# HR_C7000_DM32 register map
Vendor: Dahua Technology (chip); Baofeng (radio product); Series: HR_C7000; File version: 0.1-dm32re-draft
CPU: other r0p0, little endian, no MPU, no FPU, 0 interrupt priority bits
Registers are 32-bit, read-write, reset 0x0 unless marked. A register's access mark holds for its fields unless they carry their own. Offsets are from the block's base; [hi:lo] are bit positions.

## CODEC — Audio codec control registers, byte-wide (DS §6.5, Register Table 26, p.443-472; base 0x1600_09C0, inside the Modem_Buffer window). Mic inputs, DAC/ADC power and soft mute, digital mixer and AGC/DRC (the latter through indirect windows), gains, sample-rate selection and a countdown timer. Register names match PSPEC. FW: no access found by the movih scan (QEMU: dm32_codec logs named control writes).
Base 0x160009C0
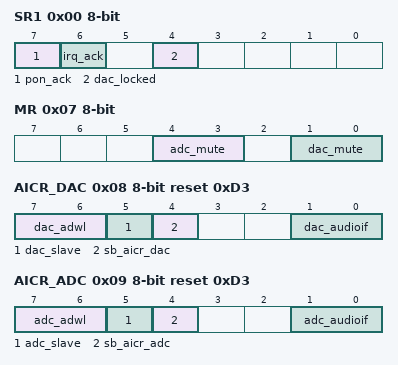
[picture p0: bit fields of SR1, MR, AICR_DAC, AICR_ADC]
0x00 SR1 8-bit ro — Status Register. DS §6.5.2.1 p.443. Reset 0x0 (DS).
  [7] pon_ack — codec power on status response 0 : codec is not in working mode; 1 : codec is in working mode [reset 0x0] [access RO]
  [6] irq_ack — Interrupt pending status register 0 : No pending interrupts are included; 1 : There is currently an unresponsive interrupt. [reset 0x0] [access RO]
  [4] dac_locked — DAC ADAS lock status, 1 is valid ( this function is in the current application Not involved ) [reset 0x0] [access RO]
0x01 SR2 8-bit ro — Status Register. DS §6.5.2.2 p.445. Reset 0x0 (DS).
  [4] dac_unknown_fs — DAC_ADAS response flag after locking: 0 : The FS of the input signal is within the frequency range supported by the codec ; 1 : The FS of the input signal exceeds the range supported by the codec ( the The performance index cannot be guaranteed). This function is not involved in the current application . [reset 0x0] [access RO]
0x07 MR 8-bit ro — ADC Mute control. DS §6.5.2.3 p.445. Reset 0x0 (DS).
  [4:3] adc_mute — 00 : ADC is not muted; 01 : ADC is being muted; 10 : ADC is about to end the mute state; 11 : ADC is in mute state [reset 0x0] [access RO]
  [1:0] dac_mute — 00 : DAC is not muted; 01 : DAC is being muted; 10 : DAC is about to end the mute state; 11 : DAC is in mute mode [reset 0x0] [access RO]
0x08 AICR_DAC 8-bit reset 0xD3 — DAC Audio interface control. DS §6.5.2.4 p.446. Reset 0xd3 (DS).
  [7:6] dac_adwl — In serial transmission mode, the DAC audio data bit width is set as follows: 00 : 16bit ; 01 : 18bit ; 10 : 20bit ; 11 : 24bit . After reset, the initial setting is 24 bits , and the internal 16-bit signal of the modem has been Expansion processing. [reset 0x3] [access RW]
  [5] dac_slave — DAC audio interface master-slave mode configuration, 0 : Master ; 1 : Slave [reset 0x0] [access RW]
  [4] sb_aicr_dac — DAC audio interface enable, 0 : active ; 1 : power- down [reset 0x1] [access RW]
  [1:0] dac_audioif — DAC audio interface mode selection, 00 : Parallel ; 01 : Left-justified ; 10 : DSP ; 11 : I2S After reset, the initial configuration is I2S mode, which needs to be fixed Parallel mode [reset 0x3] [access RW]
0x09 AICR_ADC 8-bit reset 0xD3 — ADC Audio interface control. DS §6.5.2.5 p.447. Reset 0xd3 (DS).
  [7:6] adc_adwl — In serial transmission mode, the ADC audio data bit width is set. 00 : 16bit ; 01 : 18bit ; 10 : 20bit ; 11 : 24bit After reset, the initial setting is 24 bits , and the 16-bit signal inside the modem has been expanded. [reset 0x3] [access RW]
  [5] adc_slave — ADC audio interface master-slave mode configuration, 0 : Master ; 1 : Slave [reset 0x0] [access RW]
  [4] sb_aicr_adc — ADC audio interface enable, 0 : active ; 1 : power- down [reset 0x1] [access RW]
  [1:0] adc_audioif — ADC audio interface mode selection, 00 : Parallel ; 01 : Left-justified ; 10 : DSP ; 11 : I2S After reset, the initial configuration is I2S mode, which needs to be fixed Parallel mode [reset 0x3] [access RW]
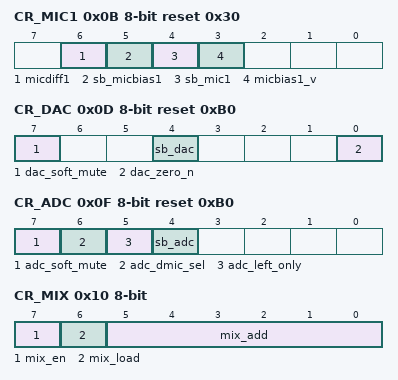
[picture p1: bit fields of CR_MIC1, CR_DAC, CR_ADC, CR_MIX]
0x0B CR_MIC1 8-bit reset 0x30 — MIC1 Control registers. DS §6.5.2.6 p.448. Reset 0x30 (DS).
  [6] micdiff1 — MIC1 input mode selection, 0 : single-ended input; 1 : differential input [reset 0x0] [access RW]
  [5] sb_micbias1 — MIC1 BIAS enable, 0 : active ; 1 : power- down [reset 0x1] [access RW]
  [4] sb_mic1 — MIC1 Enable, 0 : active ; 1 : power- down [reset 0x1] [access RW]
  [3] micbias1_v — MIC bias Voltage selection, 0 : 2.08V ; 1 : 1.66V [reset 0x0] [access RW]
0x0C CR_MIC2 8-bit reset 0x30 — MIC2 Control registers. DS §6.5.2.7 p.449. Reset 0x30 (DS).
  [6] micdiff2 — MIC1 input mode selection, 0 : AIPL1/AINL1 ; 1 : AIPL2/AINL2 [reset 0x0] [access RW]
0x0D CR_DAC 8-bit reset 0xB0 — DAC Control registers. DS §6.5.2.8 p.449. Reset 0xb0 (DS).
  [7] dac_soft_mute — DAC soft mute mode, 0 : soft mute off; 1 : soft mute on [reset 0x1] [access RW]
  [4] sb_dac — Mercury DAC operation enable, 0 : active ; 1 : power-down [reset 0x1] [access RW]
  [0] dac_zero_n — DO_LO_PWM*N pin output disabled, 0 : active ; 1 : clamp Made in VSSD [reset 0x0] [access RW]
0x0F CR_ADC 8-bit reset 0xB0 — ADC Control registers. DS §6.5.2.9 p.449. Reset 0xb0 (DS).
  [7] adc_soft_mute — ADC soft mute mode, 0 : soft mute off; 1 : soft mute on [reset 0x1] [access RW]
  [6] adc_dmic_sel — Digital filter input selection, 0 : analog mic ; 1 : digital mic (none) [reset 0x0] [access RW]
  [5] adc_left_only — ADC right channel shield, 0 : enable right channel; 1 : disable right channel [reset 0x1] [access RW]
  [4] sb_adc — ADC enable, 0 : on; 1 : off [reset 0x1] [access RW]
0x10 CR_MIX 8-bit — Digital Aliasing Control Register. DS §6.5.2.10 p.450. Window onto four indirect mixer registers (address in mix_add, data through DR_MIX at +0x11). MIX_0 (0x00): [7:6] aidacl_sel, [5:4] aidacr_sel (DAC1 modulator left/right input source: 00 same channel, 01 other channel, 10 (L+R)/2, 11 zero), [0] dac_mix (0: DAC only; 1: DAC+ADC). MIX_1 (0x01): [7:6] mixdacl_sel, [5:4] mixdacr_sel (DAC channel source into the mixer, same encoding). MIX_2 (0x02): [7:6] aiadcl_sel, [5:4] aiadcr_sel (ADC output to the port, same encoding), [0] mix_rec (0: ADC only; 1: ADC+DAC). MIX_3 (0x03): [7:6] mixadcl_sel, [5:4] mixadcr_sel (ADC channel source into the mixer, same encoding). All reset 0. Reset 0x0 (DS).
  [7] mix_en — Digital mixer enable. 0: off; 1: on [reset 0x0] [access RW]
  [6] mix_load — Indirect access direction for the mixer registers. 0: read; 1: write [reset 0x0] [access RW]
  [5:0] mix_add — Indirect address of the mixer register to access through DR_MIX [reset 0x0] [access RW]
0x11 DR_MIX 8-bit — Digital Aliasing Control Indirect. DS §6.5.2.11 p.452. Reset 0x0 (DS).
  [7:0] mix_data — Reading and writing data with digital aliased indirect addresses [reset 0x0] [access RW]
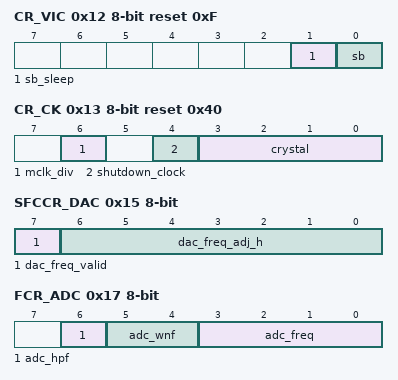
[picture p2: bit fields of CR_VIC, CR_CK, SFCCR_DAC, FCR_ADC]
0x12 CR_VIC 8-bit reset 0xF — Codec sleep Mode Control Register. DS §6.5.2.12 p.454. Reset 0xf (DS).
  [1] sb_sleep — sleep mode, 0 : active ; 1 : sleep [reset 0x1] [access RW]
  [0] sb — All codecs Simulate partial shutdown mode, 0 : active ; 1 : analog power- down [reset 0x1] [access RW]
0x13 CR_CK 8-bit reset 0x40 — MCLK Control registers. DS §6.5.2.13 p.454. Reset 0x40 (DS).
  [6] mclk_div — 0 : MCLK/1 ( reserved for Dolphin application ); 1 : MCLK/2 [reset 0x1] [access RW]
  [4] shutdown_clock — Turn off MCLK Clock, 0 : active ; 1 : MCLK Close ( Constant = 0 ), power-down Can be turned off in mode [reset 0x0] [access RW]
  [3:0] crystal — Indicates MCLK Frequency ( when MCLK_DIV=1 ), 0000 : MCLK=24MHz ; 0010 : MCLK=26MHz [reset 0x0] [access RW]
0x14 FCR_DAC 8-bit — DAC Sampling Clock Configuration. DS §6.5.2.14 p.454. Reset 0x0 (DS).
  [3:0] dac_freq — DAC Sampling clock selection, 0000: 8KHz ; others omitted [reset 0x0] [access RW]
0x15 SFCCR_DAC 8-bit — DS §6.5.2.15 p.454. Reset 0x0 (DS).
  [7] dac_freq_valid — 0 : Inactive ; 1 : master FS mode Calibration function is on ( this The configuration is fixed in the application and does not need to be changed ) [reset 0x0] [access RW]
  [6:0] dac_freq_adj_h — dac_freq_adj_h [reset 0x0] [access RW]
0x16 SFFCR_DAC 8-bit — DS §6.5.2.16 p.455. Reset 0x0 (DS).
  [7:0] dac_freq_adj_l — FS Coordination configuration word with differences between FS0 dac_freq_adj=128* ( MCLK/2 ) *(1/FS-1/FS0) ( This function is not involved in the current application ) [reset 0x0] [access RW]
0x17 FCR_ADC 8-bit — ADC Sampling Clock Configuration. DS §6.5.2.17 p.456. Reset 0x0 (DS).
  [6] adc_hpf — ADC High-pass filter enable, 0 : off; 1 : on [reset 0x0] [access RW]
  [5:4] adc_wnf — ADC Wind noise filter enable, 00 : off; 01 : ADC Wind noise filter Mode1 ; 10 : ADC Wind noise filter Mode2 ; 11 : ADC Wind noise filter Mode3 ; [reset 0x0] [access RW]
  [3:0] adc_freq — ADC Sampling clock selection, 0000: 8KHz ; others omitted [reset 0x0] [access RW]
0x18 CR_TIMER_h 8-bit — Counter high 8 bits. DS §6.5.2.18 p.456. Reset 0x0 (DS).
  [7:0] count_h — The timer counts down with a slow clock ( usually 512MCLK ). When the count reaches 0 , an interrupt is generated. The minimum timing cycle is ( 3+count ) *slow_clock ; The maximum timing cycle is ( 4+count ) *slow_clock+10*MCLK [reset 0x0] [access RW]
0x19 CR_TIMER_l 8-bit — Counter lower 8 bits. DS §6.5.2.19 p.456. Reset 0x0 (DS).
  [7:0] count_l — Used with count_h [reset 0x0] [access RW]
0x1A ICR 8-bit — Interrupt Control Register. DS §6.5.2.20 p.456. Reset 0x0 (DS).
  [7:6] int_form — IRQ output form. 00: IRQ held high; 01: IRQ held low; 10: positive pulse 8 MC_CLK wide (parallel) or 8 MCLK (I2C); 11: negative pulse, same width. Value 10 is missing from the English page and taken from the Chinese v2.7 edition p.260 [reset 0x0] [access RW]
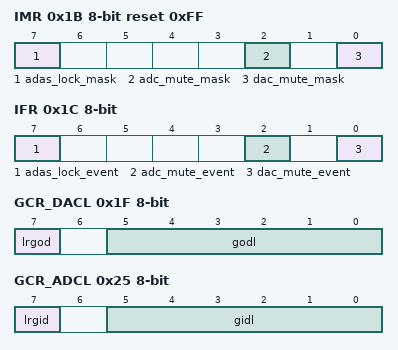
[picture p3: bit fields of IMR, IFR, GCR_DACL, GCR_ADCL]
0x1B IMR 8-bit reset 0xFF — Interrupt Mask Control registers. DS §6.5.2.21 p.458. Reset 0xff (DS).
  [7] adas_lock_mask — Block ADAS Lock sign [reset 0x1] [access RW]
  [2] adc_mute_mask — Shield ADC Mute sign [reset 0x1] [access RW]
  [0] dac_mute_mask — Shielded DAC Mute sign [reset 0x1] [access RW]
0x1C IFR 8-bit — Interrupt flag definition. DS §6.5.2.22 p.458. Reset 0x0 (DS).
  [7] adas_lock_event — ADAS Lock event flag, when DAC ADAS Locked and lost This flag is generated when switching between locks ( this function is not involved in the current application , DAC always works in Master mode ) [reset 0x0] [access RW]
  [2] adc_mute_event — ADC Soft mute mode event flag, when ADC Soft mute mode on This flag is generated when the function is enabled or disabled ( this function is not involved in the current application ) [reset 0x0] [access RW]
  [0] dac_mute_event — DAC Soft mute mode event flag, when DAC This flag is generated when the soft mute mode is turned on or off ( this function is not available in the current application) . Involved ) [reset 0x0] [access RW]
0x1D IMR2 8-bit reset 0xFF — Timer flag MASK Control registers. DS §6.5.2.23 p.458. Reset 0xff (DS).
  [4] TIMER_END_MASK — Timer interrupt mask [reset 0x1] [access RW]
0x1E IFR2 8-bit — Timer flag definition. DS §6.5.2.24 p.459. Reset 0x0 (DS).
  [4] TIMER_END — Timer count end interrupt [reset 0x0] [access RW]
0x1F GCR_DACL 8-bit — DAC Gain Control. DS §6.5.2.25 p.460. Reset 0x0 (DS).
  [7] lrgod — DAC1 left and right channels sharing the left channel is enabled. 0 : Independent configuration; 1 : Shared left channel configuration [reset 0x0] [access RW]
  [5:0] godl — DAC1 Left channel gain configuration, 011111 : -31dB ; 011110 : -30dB ; Accumulate 1dB 000001 : -1dB 000000: 0dB ; 111111: 1dB ; 111110 : 2dB ; Accumulated 1dB 100001 : 31dB ; 100000 : 32dB ; [reset 0x0] [access RW]
0x20 GCR_DACR 8-bit — DS §6.5.2.26 p.460. Reset 0x0 (DS).
  [5:0] godr — DAC1 Right channel gain configuration, 011111 : -31dB ; 011110 : -30dB ; Accumulate 1dB 000001 : -1dB 000000: 0dB ; 111111: 1dB ; 111110 : 2dB ; Accumulated 1dB 100001 : 31dB ; 100000 : 32dB ; [reset 0x0] [access RW]
0x23 GCR_MIC1 8-bit — Mic1 Gain Control. DS §6.5.2.27 p.462. Reset 0x0 (DS).
  [2:0] gim1 — MIC1 Gain step size ( boost stage ) 000: 0dB ; 001: 4dB ; 010: 8dB ; 011: 12dB ; 100 : 16dB ; other configurations are 20dB ; [reset 0x0] [access RW]
0x25 GCR_ADCL 8-bit — ADC Gain Control. DS §6.5.2.28 p.462. Reset 0x0 (DS).
  [7] lrgid — ADC The left channel is shared by the left and right channels. 0 : Independent configuration; 1 : Shared left channel configuration [reset 0x0] [access RW]
  [5:0] gidl — ADC Left channel gain configuration, 000000 : 0dB ; 000001 : 1dB ; Accumulated 1dB 101010 : 42dB ; Others: 43dB ; When gidl When the value changes, the ADC Data output at 64 In addition, the activation of the high-pass filter will also introduce a delay in the path. [reset 0x0] [access RW]
0x26 GCR_ADCR 8-bit — DS §6.5.2.29 p.462. Reset 0x0 (DS).
  [5:0] gidr — ADC Right channel gain configuration, 000000 : 0dB ; 000001 : 1dB ; Accumulated 1dB 101010 : 42dB ; Others : 43dB ; [reset 0x0] [access RW]
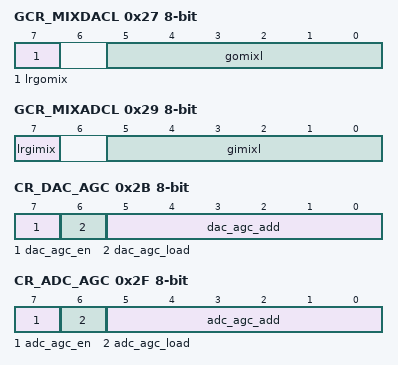
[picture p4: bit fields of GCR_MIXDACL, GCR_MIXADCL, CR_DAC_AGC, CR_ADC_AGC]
0x27 GCR_MIXDACL 8-bit — Aliasing DAC Gain Control. DS §6.5.2.30 p.463. Reset 0x0 (DS).
  [7] lrgomix — Aliasing DAC The left and right channel gains share the configuration of the left channel. 0 : Independent configuration; 1 : Shared left channel configuration [reset 0x0] [access RW]
  [5:0] gomixl — Aliasing DAC Left channel gain configuration, 000000 : 0dB ; 000001 : -1dB ; Decrease by 1dB 011111 : -31dB ; [reset 0x0] [access RW]
0x28 GCR_MIXDACR 8-bit — DS §6.5.2.31 p.464. Reset 0x0 (DS).
  [5:0] gomixr — Aliasing DAC Right channel gain configuration, 000000 : 0dB ; 000001 : -1dB ; Decrease by 1dB 011111 : -31dB ; [reset 0x0] [access RW]
0x29 GCR_MIXADCL 8-bit — Aliasing ADC Gain Control. DS §6.5.2.32 p.464. Reset 0x0 (DS).
  [7] lrgimix — Aliasing ADC The left and right channel gains share the configuration of the left channel. 0 : Independent configuration; 1 : Shared left channel configuration [reset 0x0] [access RW]
  [5:0] gimixl — Aliasing ADC Left channel gain configuration, 000000 : 0dB ; 000001 : -1dB ; Decrease by 1dB 011111 : -31dB ; [reset 0x0] [access RW]
0x2A GCR_MIXADCR 8-bit — DS §6.5.2.33 p.465. Reset 0x0 (DS).
  [5:0] gimixr — Aliasing ADC Right channel gain configuration, 000000 : 0dB ; 000001 : -1dB ; Decrease by 1dB 011111 : -31dB ; [reset 0x0] [access RW]
0x2B CR_DAC_AGC 8-bit — DAC Gain Control Register. DS §6.5.2.34 p.466. Reset 0x0 (DS).
  [7] dac_agc_en — DAC AGC Enable, 0 : Automatic gain off; 1 : Automatic gain on [reset 0x0] [access RW]
  [6] dac_agc_load — DAC AGC Indirect address space read and write control 0 : read; 1 : write [reset 0x0] [access RW]
  [5:0] dac_agc_add — DAC AGC Indirect Address [reset 0x0] [access RW]
0x2C DR_DAC_AGC 8-bit — DAC AGC Read and write data of indirect. DS §6.5.2.35 p.466. Indirect DAC1 DRC registers (index in CR_DAC_AGC): DAC_AGC_0 (0x00): [7] lr_drc (1: right channel uses left's configuration), [4:0] lthres (left compression threshold, 0 to -31 dB in 1 dB steps). DAC_AGC_1 (0x01): [2:0] lcomp (left compression ratio 1, 2, 4 ... 32). DAC_AGC_2 (0x02): [4:0] rthres. DAC_AGC_3 (0x03): [2:0] rcomp. All reset 0. Reset 0x0 (DS).
  [7:0] dac_agc_data — Data for the DAC AGC/DRC register selected by CR_DAC_AGC.dac_agc_add [reset 0x0] [access RW]
0x2F CR_ADC_AGC 8-bit — ADC Gain Control Register. DS §6.5.2.36 p.468. Reset 0x0 (DS).
  [7] adc_agc_en — ADC AGC Enable, 0 : Automatic gain off; 1 : Automatic gain on [reset 0x0] [access RW]
  [6] adc_agc_load — ADC AGC Indirect address space read and write control 0 : read; 1 : write [reset 0x0] [access RW]
  [5:0] adc_agc_add — ADC AGC Indirect Address [reset 0x0] [access RW]
0x30 DR_ADC_AGC 8-bit — ADC AGC Read and write data of indirect. DS §6.5.2.37 p.468. Indirect ADC AGC registers (index in CR_ADC_AGC): ADC_AGC_0 (0x00): [6] agc_stereo (1: right uses left's configuration), [5:2] target (output amplitude target, Max_target minus 1.5 dB per step, reset 0xd). ADC_AGC_1 (0x01): [7] ng_en (noise gate), [6:4] ng_thr (MIN_NG_THR + 6 dB per step), [3:0] hold (time before AGC acts, 0 ms, 2 ms, doubling to 32.768 s; reset 0x7). ADC_AGC_2 (0x02): [7:4] atk, [3:0] dcy (gain ramp fall/rise time, 0010 = 96 ms then +32 ms per step to 512 ms; reset 0x4 each). ADC_AGC_3 (0x03): [4:0] agc_max (max gain, reset 0x1f). ADC_AGC_4 (0x04): [4:0] agc_min (min gain, reset 0). Gain codes: 1.5 dB steps to 22.5 dB at 01111, then 23, 23, 23, 24.5 ... 42.5 dB at 11111. Reset 0x0 (DS).
  [7:0] adc_agc_data — Data for the ADC AGC register selected by CR_ADC_AGC.adc_agc_add [reset 0x0] [access RW]
